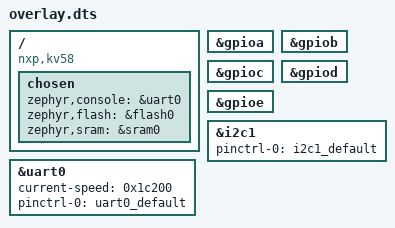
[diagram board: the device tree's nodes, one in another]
/ {
	compatible = "nxp,kv58", "nxp,kv5x", "nxp,mkv58f24";
	chosen {
		zephyr,console = &uart0;
		zephyr,flash = &flash0;
		zephyr,sram = &sram0;
	};
};
&gpioa{
	status = "okay";
};
&gpiob{
	status = "okay";
};
&gpioc{
	status = "okay";
};
&gpiod{
	status = "okay";
};
&gpioe{
	status = "okay";
};
&i2c1{
	status = "okay";
	pinctrl-0 = < &i2c1_default >;
	pinctrl-names = "default";
};
&uart0{
	status = "okay";
	current-speed = < 0x1c200 >;
	pinctrl-0 = < &uart0_default >;
	pinctrl-names = "default";
};
